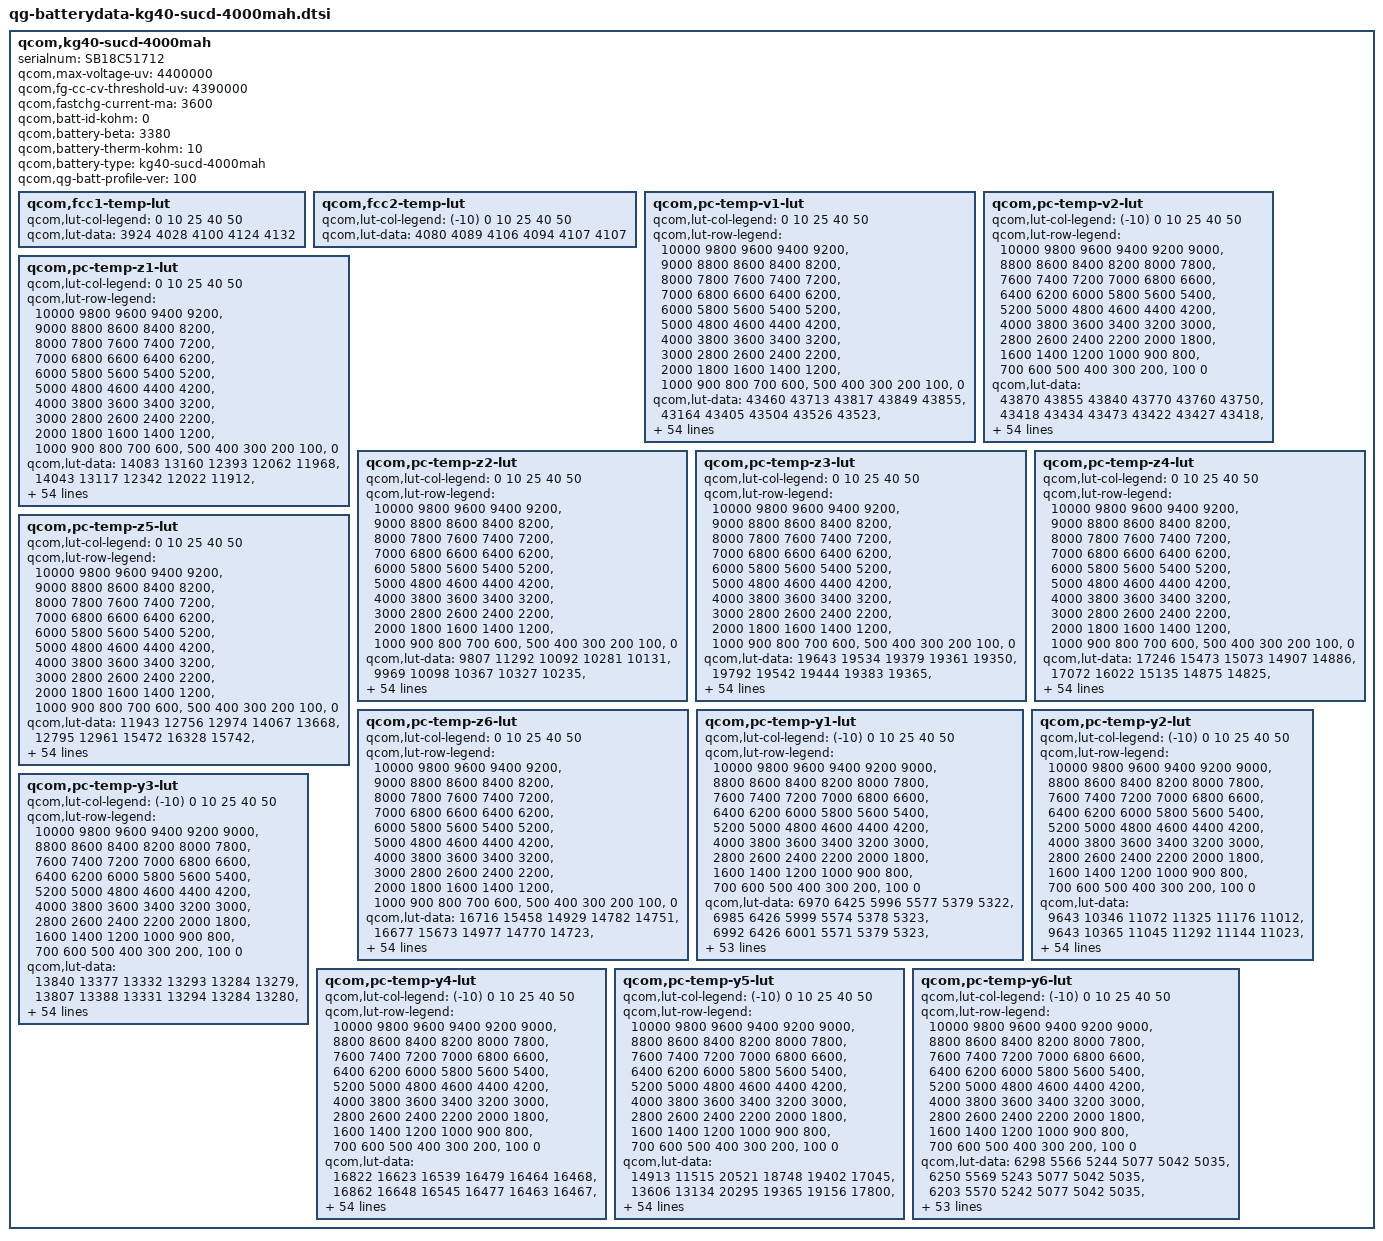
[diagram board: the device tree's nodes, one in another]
qcom,kg40-sucd-4000mah {
    /* 4123832_Huaqin_QL1883_SCUD_4000mAH_PMI632_averaged_MasterSlave_Aug21th2019 */
    serialnum = "SB18C51712";
    qcom,max-voltage-uv = <4400000>;
    qcom,fg-cc-cv-threshold-uv = <4390000>;
    qcom,fastchg-current-ma = <3600>;
    qcom,batt-id-kohm = <0>;
    qcom,battery-beta = <3380>;
    qcom,battery-therm-kohm = <10>;
    qcom,battery-type = "kg40-sucd-4000mah";
    qcom,qg-batt-profile-ver = <100>;

	qcom,fcc1-temp-lut {
		qcom,lut-col-legend = <0 10 25 40 50>;
		qcom,lut-data = <3924 4028 4100 4124 4132>;
	};

	qcom,fcc2-temp-lut {
		qcom,lut-col-legend = <(-10) 0 10 25 40 50>;
		qcom,lut-data = <4080 4089 4106 4094 4107 4107>;
	};

	qcom,pc-temp-v1-lut {
		qcom,lut-col-legend = <0 10 25 40 50>;
		qcom,lut-row-legend = <10000 9800 9600 9400 9200>,
			<9000 8800 8600 8400 8200>,
			<8000 7800 7600 7400 7200>,
			<7000 6800 6600 6400 6200>,
			<6000 5800 5600 5400 5200>,
			<5000 4800 4600 4400 4200>,
			<4000 3800 3600 3400 3200>,
			<3000 2800 2600 2400 2200>,
			<2000 1800 1600 1400 1200>,
			<1000 900 800 700 600>,
			<500 400 300 200 100>,
			<0>;
		qcom,lut-data = <43460 43713 43817 43849 43855>,
			<43164 43405 43504 43526 43523>,
			<42900 43133 43234 43255 43247>,
			<42664 42876 42982 43007 43000>,
			<42441 42632 42736 42766 42763>,
			<42220 42399 42493 42527 42527>,
			<42005 42171 42258 42294 42295>,
			<41794 41950 42031 42061 42065>,
			<41584 41734 41809 41831 41837>,
			<41382 41515 41589 41605 41611>,
			<41208 41306 41366 41382 41386>,
			<41050 41134 41157 41165 41167>,
			<40855 40986 40980 40957 40955>,
			<40555 40796 40809 40758 40752>,
			<40247 40483 40584 40558 40554>,
			<40042 40174 40296 40354 40360>,
			<39884 39999 40069 40161 40174>,
			<39750 39875 39933 39991 40000>,
			<39635 39756 39818 39833 39834>,
			<39530 39639 39687 39684 39680>,
			<39420 39520 39549 39548 39543>,
			<39308 39391 39379 39387 39384>,
			<39195 39252 39129 39128 39135>,
			<39082 39084 38889 38862 38870>,
			<38970 38844 38736 38717 38720>,
			<38861 38626 38619 38623 38621>,
			<38756 38505 38525 38533 38528>,
			<38656 38417 38452 38440 38429>,
			<38560 38357 38385 38353 38336>,
			<38469 38317 38316 38275 38255>,
			<38394 38283 38252 38203 38183>,
			<38328 38249 38193 38139 38119>,
			<38275 38215 38140 38084 38064>,
			<38236 38182 38092 38033 38011>,
			<38207 38150 38054 37988 37960>,
			<38176 38117 38018 37945 37910>,
			<38146 38088 37981 37900 37857>,
			<38112 38057 37945 37854 37803>,
			<38068 38012 37897 37796 37738>,
			<38013 37939 37820 37717 37652>,
			<37939 37846 37723 37621 37551>,
			<37825 37734 37617 37515 37443>,
			<37687 37599 37492 37392 37320>,
			<37525 37442 37336 37236 37159>,
			<37375 37288 37182 37087 37013>,
			<37256 37173 37075 36990 36930>,
			<37215 37135 37048 36964 36905>,
			<37181 37120 37028 36944 36885>,
			<37153 37097 37010 36926 36868>,
			<37121 37070 36983 36895 36829>,
			<37010 36947 36829 36709 36618>,
			<36622 36544 36427 36294 36199>,
			<36066 35987 35862 35729 35633>,
			<35308 35223 35095 34959 34858>,
			<34121 34039 33907 33766 33659>,
			<30000 30000 30000 30000 30000>;
	};

	qcom,pc-temp-v2-lut {
		qcom,lut-col-legend = <(-10) 0 10 25 40 50>;
		qcom,lut-row-legend = <10000 9800 9600 9400 9200 9000>,
			<8800 8600 8400 8200 8000 7800>,
			<7600 7400 7200 7000 6800 6600>,
			<6400 6200 6000 5800 5600 5400>,
			<5200 5000 4800 4600 4400 4200>,
			<4000 3800 3600 3400 3200 3000>,
			<2800 2600 2400 2200 2000 1800>,
			<1600 1400 1200 1000 900 800>,
			<700 600 500 400 300 200>,
			<100 0>;
		qcom,lut-data = <43870 43855 43840 43770 43760 43750>,
			<43418 43434 43473 43422 43427 43418>,
			<43023 43066 43143 43108 43123 43115>,
			<42693 42765 42856 42833 42852 42846>,
			<42414 42516 42606 42593 42611 42606>,
			<42171 42276 42364 42358 42376 42372>,
			<41969 42038 42126 42124 42142 42138>,
			<41779 41802 41894 41893 41911 41907>,
			<41542 41551 41666 41667 41683 41679>,
			<41269 41287 41442 41444 41459 41454>,
			<41090 41087 41235 41227 41238 41233>,
			<41015 40967 41054 41021 41022 41017>,
			<40936 40842 40868 40815 40810 40805>,
			<40640 40602 40635 40598 40606 40601>,
			<40064 40258 40374 40377 40406 40402>,
			<39687 39976 40143 40177 40216 40211>,
			<39491 39754 39939 39995 40035 40028>,
			<39330 39559 39754 39828 39863 39854>,
			<39166 39384 39595 39684 39702 39692>,
			<39013 39224 39445 39549 39548 39536>,
			<38862 39055 39262 39382 39385 39377>,
			<38711 38875 39041 39172 39216 39218>,
			<38573 38708 38841 38963 39034 39043>,
			<38445 38560 38677 38764 38810 38816>,
			<38330 38426 38533 38580 38593 38594>,
			<38239 38303 38409 38442 38451 38450>,
			<38164 38187 38301 38334 38345 38343>,
			<38098 38099 38202 38239 38250 38247>,
			<38038 38037 38108 38155 38162 38158>,
			<37982 37987 38025 38080 38083 38077>,
			<37930 37943 37957 38010 38014 38006>,
			<37881 37904 37899 37943 37951 37941>,
			<37832 37865 37854 37884 37891 37881>,
			<37782 37827 37821 37831 37834 37827>,
			<37731 37789 37791 37782 37775 37769>,
			<37676 37748 37758 37734 37708 37694>,
			<37616 37705 37725 37687 37636 37607>,
			<37554 37655 37683 37632 37559 37517>,
			<37489 37597 37631 37568 37477 37419>,
			<37422 37529 37566 37496 37394 37326>,
			<37357 37446 37484 37416 37318 37249>,
			<37291 37346 37383 37322 37232 37167>,
			<37223 37227 37260 37202 37124 37063>,
			<37153 37109 37122 37072 36985 36924>,
			<37071 37006 36988 36938 36858 36798>,
			<36967 36924 36906 36873 36805 36749>,
			<36910 36890 36881 36859 36795 36739>,
			<36841 36854 36845 36841 36783 36727>,
			<36736 36815 36808 36823 36761 36706>,
			<36573 36722 36735 36762 36701 36636>,
			<36271 36508 36513 36554 36455 36367>,
			<35839 36080 36062 36083 35971 35871>,
			<35237 35457 35431 35460 35328 35224>,
			<34380 34561 34551 34630 34471 34353>,
			<33024 33296 33337 33371 33257 33129>,
			<29294 28717 28615 28260 28466 28435>;
	};

	qcom,pc-temp-z1-lut {
		qcom,lut-col-legend = <0 10 25 40 50>;
		qcom,lut-row-legend = <10000 9800 9600 9400 9200>,
			<9000 8800 8600 8400 8200>,
			<8000 7800 7600 7400 7200>,
			<7000 6800 6600 6400 6200>,
			<6000 5800 5600 5400 5200>,
			<5000 4800 4600 4400 4200>,
			<4000 3800 3600 3400 3200>,
			<3000 2800 2600 2400 2200>,
			<2000 1800 1600 1400 1200>,
			<1000 900 800 700 600>,
			<500 400 300 200 100>,
			<0>;
		qcom,lut-data = <14083 13160 12393 12062 11968>,
			<14043 13117 12342 12022 11912>,
			<14018 13088 12329 11999 11903>,
			<14003 13072 12314 11991 11898>,
			<13988 13063 12303 11987 11895>,
			<13966 13059 12293 11984 11895>,
			<13942 13053 12285 11982 11895>,
			<13930 13035 12280 11983 11897>,
			<13919 13025 12275 11985 11901>,
			<13909 13025 12275 11986 11903>,
			<13906 13023 12281 11986 11903>,
			<13902 13013 12284 11987 11903>,
			<13893 12991 12283 11987 11903>,
			<13858 12970 12280 11987 11904>,
			<13812 12952 12275 11987 11904>,
			<13776 12939 12262 11987 11905>,
			<13734 12941 12256 11987 11906>,
			<13716 12949 12262 11988 11908>,
			<13725 12957 12273 11989 11910>,
			<13736 12964 12281 11992 11912>,
			<13737 12973 12290 11995 11913>,
			<13735 12984 12296 11998 11915>,
			<13739 12997 12301 12000 11917>,
			<13755 13006 12304 12002 11918>,
			<13777 13015 12308 12005 11921>,
			<13794 13021 12312 12009 11925>,
			<13809 13028 12317 12013 11928>,
			<13819 13035 12324 12018 11932>,
			<13820 13037 12330 12023 11935>,
			<13816 13033 12336 12027 11938>,
			<13816 13029 12342 12031 11941>,
			<13816 13044 12347 12033 11944>,
			<13820 13078 12351 12036 11947>,
			<13829 13092 12355 12038 11950>,
			<13841 13091 12363 12042 11952>,
			<13861 13091 12373 12047 11955>,
			<13909 13096 12380 12052 11958>,
			<13949 13107 12386 12056 11961>,
			<13949 13118 12393 12060 11964>,
			<13942 13131 12400 12065 11968>,
			<13936 13141 12407 12070 11971>,
			<13935 13150 12418 12074 11974>,
			<13942 13160 12430 12078 11977>,
			<13993 13185 12432 12082 11979>,
			<13972 13187 12439 12088 11982>,
			<13968 13201 12453 12090 11983>,
			<13964 13205 12448 12090 11983>,
			<13930 13179 12448 12092 11984>,
			<13961 13185 12455 12092 11986>,
			<13969 13186 12460 12098 11991>,
			<13992 13211 12467 12104 11996>,
			<14020 13240 12476 12112 12004>,
			<14010 13240 12506 12126 12014>,
			<14064 13295 12523 12143 12028>,
			<14064 13295 12523 12143 12028>,
			<14064 13295 12523 12143 12028>;
	};

	qcom,pc-temp-z2-lut {
		qcom,lut-col-legend = <0 10 25 40 50>;
		qcom,lut-row-legend = <10000 9800 9600 9400 9200>,
			<9000 8800 8600 8400 8200>,
			<8000 7800 7600 7400 7200>,
			<7000 6800 6600 6400 6200>,
			<6000 5800 5600 5400 5200>,
			<5000 4800 4600 4400 4200>,
			<4000 3800 3600 3400 3200>,
			<3000 2800 2600 2400 2200>,
			<2000 1800 1600 1400 1200>,
			<1000 900 800 700 600>,
			<500 400 300 200 100>,
			<0>;
		qcom,lut-data = <9807 11292 10092 10281 10131>,
			<9969 10098 10367 10327 10235>,
			<10049 10134 10383 10411 10350>,
			<10092 10151 10372 10397 10364>,
			<10112 10128 10359 10379 10369>,
			<10104 10092 10322 10352 10348>,
			<10081 10065 10294 10324 10309>,
			<10064 10040 10478 10315 10289>,
			<10055 10026 10863 10309 10276>,
			<10046 10019 11017 10310 10272>,
			<10034 10014 11073 10317 10286>,
			<10019 10072 11095 10325 10303>,
			<10002 10250 11067 10328 10290>,
			<9977 10322 10996 10331 10246>,
			<9951 10215 10845 10332 10224>,
			<9931 10101 10510 10331 10215>,
			<9914 10099 10342 10328 10213>,
			<9907 10120 10337 10314 10224>,
			<9909 10145 10335 10291 10245>,
			<9914 10176 10348 10289 10268>,
			<9918 10209 10393 10308 10294>,
			<9924 10241 10433 10340 10336>,
			<9930 10273 10469 10512 10515>,
			<9937 10281 10492 10714 10732>,
			<9944 10266 10454 10666 10705>,
			<9955 10252 10364 10430 10493>,
			<9977 10259 10342 10334 10395>,
			<10000 10279 10374 10415 10414>,
			<10021 10290 10402 10495 10434>,
			<10040 10295 10405 10464 10397>,
			<10057 10299 10407 10381 10291>,
			<10073 10304 10407 10344 10223>,
			<10088 10310 10405 10330 10181>,
			<10100 10318 10404 10324 10161>,
			<10112 10330 10409 10340 10182>,
			<10128 10344 10420 10375 10230>,
			<10153 10357 10435 10411 10278>,
			<10178 10372 10459 10453 10334>,
			<10181 10389 10483 10480 10378>,
			<10163 10413 10506 10494 10409>,
			<10165 10436 10526 10502 10431>,
			<10203 10451 10540 10508 10438>,
			<10242 10466 10551 10520 10443>,
			<10281 10483 10552 10517 10481>,
			<10000 10590 10566 10498 10498>,
			<10023 10720 10605 10477 10405>,
			<11487 10724 10606 10483 10418>,
			<9940 11479 10621 10486 10428>,
			<9979 11787 10598 10493 10467>,
			<10034 11837 10633 10588 10558>,
			<9947 11635 10664 10492 10422>,
			<9870 10790 10621 10367 10247>,
			<9801 10785 10555 10287 10170>,
			<9677 10702 10481 10238 10096>,
			<9677 10702 10481 10238 10096>,
			<9677 10702 10481 10238 10096>;
	};

	qcom,pc-temp-z3-lut {
		qcom,lut-col-legend = <0 10 25 40 50>;
		qcom,lut-row-legend = <10000 9800 9600 9400 9200>,
			<9000 8800 8600 8400 8200>,
			<8000 7800 7600 7400 7200>,
			<7000 6800 6600 6400 6200>,
			<6000 5800 5600 5400 5200>,
			<5000 4800 4600 4400 4200>,
			<4000 3800 3600 3400 3200>,
			<3000 2800 2600 2400 2200>,
			<2000 1800 1600 1400 1200>,
			<1000 900 800 700 600>,
			<500 400 300 200 100>,
			<0>;
		qcom,lut-data = <19643 19534 19379 19361 19350>,
			<19792 19542 19444 19383 19365>,
			<19821 19627 19473 19415 19404>,
			<19772 19669 19482 19420 19410>,
			<19720 19668 19483 19422 19412>,
			<19697 19668 19483 19424 19414>,
			<19680 19664 19483 19426 19415>,
			<19677 19655 19491 19425 19414>,
			<19686 19648 19508 19420 19410>,
			<19697 19644 19511 19416 19406>,
			<19703 19640 19506 19410 19404>,
			<19708 19638 19499 19404 19402>,
			<19717 19636 19492 19399 19397>,
			<19771 19632 19483 19393 19388>,
			<19828 19622 19474 19391 19382>,
			<19825 19607 19463 19390 19378>,
			<19789 19586 19453 19390 19376>,
			<19758 19558 19442 19386 19372>,
			<19739 19542 19431 19379 19368>,
			<19723 19536 19422 19372 19363>,
			<19709 19533 19415 19364 19354>,
			<19696 19532 19414 19361 19349>,
			<19690 19532 19429 19375 19361>,
			<19696 19533 19444 19394 19377>,
			<19707 19543 19438 19388 19374>,
			<19712 19552 19423 19362 19355>,
			<19716 19552 19418 19352 19347>,
			<19718 19553 19420 19376 19378>,
			<19718 19553 19422 19401 19411>,
			<19715 19550 19429 19405 19410>,
			<19712 19547 19438 19407 19402>,
			<19705 19543 19440 19406 19393>,
			<19696 19539 19439 19400 19383>,
			<19684 19536 19439 19392 19373>,
			<19670 19533 19435 19386 19365>,
			<19655 19530 19430 19380 19359>,
			<19640 19525 19425 19375 19355>,
			<19621 19518 19421 19371 19351>,
			<19579 19513 19418 19368 19350>,
			<19506 19509 19417 19366 19350>,
			<19475 19505 19415 19365 19350>,
			<19474 19500 19411 19363 19351>,
			<19473 19495 19406 19362 19351>,
			<19462 19488 19404 19362 19355>,
			<19332 19463 19399 19361 19358>,
			<19266 19438 19390 19354 19347>,
			<19262 19438 19384 19348 19340>,
			<19266 19309 19378 19344 19335>,
			<19265 19287 19374 19342 19324>,
			<19264 19281 19369 19331 19320>,
			<19265 19297 19374 19347 19336>,
			<19266 19426 19375 19362 19351>,
			<19267 19383 19383 19364 19354>,
			<19270 19387 19374 19363 19359>,
			<19270 19387 19374 19363 19359>,
			<19270 19387 19374 19363 19359>;
	};

	qcom,pc-temp-z4-lut {
		qcom,lut-col-legend = <0 10 25 40 50>;
		qcom,lut-row-legend = <10000 9800 9600 9400 9200>,
			<9000 8800 8600 8400 8200>,
			<8000 7800 7600 7400 7200>,
			<7000 6800 6600 6400 6200>,
			<6000 5800 5600 5400 5200>,
			<5000 4800 4600 4400 4200>,
			<4000 3800 3600 3400 3200>,
			<3000 2800 2600 2400 2200>,
			<2000 1800 1600 1400 1200>,
			<1000 900 800 700 600>,
			<500 400 300 200 100>,
			<0>;
		qcom,lut-data = <17246 15473 15073 14907 14886>,
			<17072 16022 15135 14875 14825>,
			<16839 15713 15165 14953 14889>,
			<16513 15444 15027 14902 14858>,
			<16203 15279 14933 14850 14822>,
			<15989 15149 14884 14818 14797>,
			<15813 15055 14840 14792 14775>,
			<15668 14982 14782 14768 14756>,
			<15549 14926 14724 14747 14739>,
			<15444 14888 14697 14735 14728>,
			<15339 14852 14686 14730 14720>,
			<15239 14797 14676 14725 14714>,
			<15163 14725 14660 14719 14711>,
			<15110 14700 14646 14711 14709>,
			<15066 14743 14655 14705 14706>,
			<15025 14790 14705 14702 14702>,
			<14987 14786 14732 14699 14697>,
			<14951 14762 14709 14694 14693>,
			<14914 14740 14682 14689 14689>,
			<14880 14717 14680 14686 14684>,
			<14857 14702 14682 14684 14680>,
			<14841 14701 14688 14683 14678>,
			<14825 14701 14748 14741 14733>,
			<14804 14709 14814 14819 14811>,
			<14786 14789 14835 14835 14822>,
			<14776 14864 14848 14840 14823>,
			<14770 14866 14848 14840 14821>,
			<14768 14865 14822 14798 14773>,
			<14771 14860 14791 14747 14718>,
			<14776 14835 14764 14726 14707>,
			<14778 14805 14739 14712 14703>,
			<14777 14783 14724 14703 14699>,
			<14775 14764 14714 14698 14695>,
			<14769 14748 14708 14695 14693>,
			<14757 14734 14704 14692 14691>,
			<14748 14723 14702 14691 14689>,
			<14741 14712 14698 14691 14689>,
			<14736 14703 14694 14692 14691>,
			<14755 14698 14692 14693 14694>,
			<14815 14696 14695 14699 14701>,
			<14838 14693 14697 14705 14709>,
			<14827 14689 14693 14701 14705>,
			<14818 14684 14682 14691 14693>,
			<14814 14681 14679 14691 14695>,
			<14890 14674 14672 14686 14692>,
			<14931 14663 14651 14664 14665>,
			<14924 14654 14645 14658 14661>,
			<14915 14790 14638 14646 14650>,
			<14909 14809 14632 14629 14637>,
			<14904 14811 14633 14630 14627>,
			<14904 14796 14641 14640 14648>,
			<14928 14671 14657 14647 14656>,
			<14946 14732 14657 14651 14659>,
			<14963 14740 14673 14657 14658>,
			<14963 14740 14673 14657 14658>,
			<14963 14740 14673 14657 14658>;
	};

	qcom,pc-temp-z5-lut {
		qcom,lut-col-legend = <0 10 25 40 50>;
		qcom,lut-row-legend = <10000 9800 9600 9400 9200>,
			<9000 8800 8600 8400 8200>,
			<8000 7800 7600 7400 7200>,
			<7000 6800 6600 6400 6200>,
			<6000 5800 5600 5400 5200>,
			<5000 4800 4600 4400 4200>,
			<4000 3800 3600 3400 3200>,
			<3000 2800 2600 2400 2200>,
			<2000 1800 1600 1400 1200>,
			<1000 900 800 700 600>,
			<500 400 300 200 100>,
			<0>;
		qcom,lut-data = <11943 12756 12974 14067 13668>,
			<12795 12961 15472 16328 15742>,
			<13142 14063 15811 16997 18124>,
			<13246 15042 16735 17531 18912>,
			<13332 15634 17565 18103 19467>,
			<13460 16162 18150 18694 20106>,
			<13609 16734 18927 19313 20701>,
			<13793 17324 20935 19977 21294>,
			<14046 18056 24131 20737 21873>,
			<14323 19029 26621 21196 22503>,
			<14550 20285 28496 21292 23441>,
			<14759 22299 30428 21259 24200>,
			<15182 25218 33292 21236 23897>,
			<17245 26688 35882 21279 22814>,
			<19370 26936 34934 21603 22452>,
			<19327 26784 29235 22667 23055>,
			<18379 25475 26224 23679 23831>,
			<17830 22692 26585 24206 24501>,
			<17875 21740 27112 24582 25160>,
			<18051 23750 27401 24474 25140>,
			<18260 26911 27833 23576 24095>,
			<18566 29868 29168 23075 23412>,
			<19069 33306 39935 28565 26870>,
			<20814 37895 49952 35703 31842>,
			<23851 46273 44114 33012 29990>,
			<27101 52518 29364 21348 20342>,
			<31201 50722 23544 16527 15977>,
			<35117 45256 22088 18176 20005>,
			<38853 41174 21499 20750 24839>,
			<42287 38206 22874 23421 26375>,
			<43136 36259 26070 26409 27272>,
			<42942 35531 29269 28447 27408>,
			<42536 35084 32973 29871 26780>,
			<40873 35132 35691 30930 26282>,
			<37115 36514 37323 31859 26631>,
			<33710 37946 38352 32585 27309>,
			<30789 38128 38395 32621 27597>,
			<27968 37797 38125 32185 27597>,
			<24596 38143 37820 31538 27451>,
			<20481 39563 37376 30171 26763>,
			<18987 40549 36655 28454 25856>,
			<20463 39813 34728 27068 25347>,
			<21441 38080 32055 26010 24980>,
			<21271 35575 31752 26318 27433>,
			<14954 31821 32182 26799 29507>,
			<11535 27993 32869 26215 26237>,
			<11483 28963 29328 23395 21966>,
			<11505 12720 27120 23867 22201>,
			<11483 11954 26269 27206 21733>,
			<11495 11841 24842 22664 23209>,
			<11528 12304 24836 26455 25233>,
			<11597 23305 21237 24789 22799>,
			<11490 16920 21761 22759 20749>,
			<11419 16004 18097 19746 19447>,
			<11419 16004 18097 19746 19447>,
			<11419 16004 18097 19746 19447>;
	};

	qcom,pc-temp-z6-lut {
		qcom,lut-col-legend = <0 10 25 40 50>;
		qcom,lut-row-legend = <10000 9800 9600 9400 9200>,
			<9000 8800 8600 8400 8200>,
			<8000 7800 7600 7400 7200>,
			<7000 6800 6600 6400 6200>,
			<6000 5800 5600 5400 5200>,
			<5000 4800 4600 4400 4200>,
			<4000 3800 3600 3400 3200>,
			<3000 2800 2600 2400 2200>,
			<2000 1800 1600 1400 1200>,
			<1000 900 800 700 600>,
			<500 400 300 200 100>,
			<0>;
		qcom,lut-data = <16716 15458 14929 14782 14751>,
			<16677 15673 14977 14770 14723>,
			<16590 15564 15000 14817 14767>,
			<16403 15459 14944 14797 14756>,
			<16209 15381 14903 14776 14743>,
			<16085 15312 14878 14763 14734>,
			<15983 15259 14858 14752 14726>,
			<15906 15216 14839 14741 14717>,
			<15849 15182 14823 14731 14708>,
			<15799 15159 14813 14723 14702>,
			<15745 15138 14806 14717 14697>,
			<15691 15107 14799 14712 14694>,
			<15657 15069 14786 14706 14689>,
			<15641 15056 14773 14699 14683>,
			<15627 15058 14773 14696 14678>,
			<15599 15061 14784 14694 14675>,
			<15554 15053 14789 14692 14671>,
			<15515 15028 14775 14688 14667>,
			<15486 15011 14758 14682 14664>,
			<15463 15001 14755 14677 14659>,
			<15448 14996 14754 14673 14653>,
			<15437 14996 14755 14671 14649>,
			<15432 14999 14792 14705 14679>,
			<15433 15006 14828 14749 14722>,
			<15436 15046 14832 14752 14726>,
			<15439 15084 14833 14743 14719>,
			<15442 15088 14832 14736 14712>,
			<15446 15090 14823 14731 14708>,
			<15452 15089 14813 14725 14704>,
			<15459 15080 14807 14720 14700>,
			<15460 15067 14802 14716 14694>,
			<15457 15059 14797 14711 14688>,
			<15453 15051 14794 14705 14682>,
			<15448 15045 14791 14701 14676>,
			<15441 15039 14788 14696 14670>,
			<15434 15035 14785 14693 14666>,
			<15428 15032 14783 14690 14664>,
			<15423 15029 14780 14689 14663>,
			<15419 15029 14779 14688 14663>,
			<15415 15030 14781 14690 14666>,
			<15414 15031 14783 14692 14670>,
			<15415 15032 14781 14690 14669>,
			<15417 15032 14775 14686 14664>,
			<15419 15031 14775 14686 14668>,
			<15400 15025 14772 14684 14668>,
			<15387 15010 14760 14672 14651>,
			<15385 15008 14755 14667 14646>,
			<15382 15000 14749 14659 14638>,
			<15380 14999 14745 14651 14627>,
			<15380 15000 14744 14646 14621>,
			<15391 15008 14753 14660 14639>,
			<15410 15027 14764 14673 14653>,
			<15431 15042 14773 14679 14659>,
			<15461 15064 14782 14685 14665>,
			<15461 15064 14782 14685 14665>,
			<15461 15064 14782 14685 14665>;
	};

	qcom,pc-temp-y1-lut {
		qcom,lut-col-legend = <(-10) 0 10 25 40 50>;
		qcom,lut-row-legend = <10000 9800 9600 9400 9200 9000>,
			<8800 8600 8400 8200 8000 7800>,
			<7600 7400 7200 7000 6800 6600>,
			<6400 6200 6000 5800 5600 5400>,
			<5200 5000 4800 4600 4400 4200>,
			<4000 3800 3600 3400 3200 3000>,
			<2800 2600 2400 2200 2000 1800>,
			<1600 1400 1200 1000 900 800>,
			<700 600 500 400 300 200>,
			<100 0>;
		qcom,lut-data = <6970 6425 5996 5577 5379 5322>,
			<6985 6426 5999 5574 5378 5323>,
			<6992 6426 6001 5571 5379 5323>,
			<6992 6424 6002 5568 5379 5324>,
			<6987 6421 6002 5565 5380 5324>,
			<6978 6418 6001 5563 5380 5325>,
			<6949 6411 5998 5563 5380 5325>,
			<6917 6406 5994 5562 5381 5326>,
			<6917 6407 5991 5562 5381 5326>,
			<6927 6413 5987 5561 5381 5326>,
			<6932 6416 5985 5561 5381 5326>,
			<6928 6412 5983 5560 5382 5326>,
			<6925 6408 5982 5559 5382 5327>,
			<6939 6412 5981 5559 5382 5328>,
			<6978 6422 5978 5561 5382 5329>,
			<6996 6431 5981 5564 5382 5330>,
			<6995 6443 5994 5571 5385 5330>,
			<6993 6451 6005 5576 5387 5331>,
			<6996 6447 6003 5575 5388 5332>,
			<6999 6439 5998 5573 5388 5333>,
			<6995 6439 5999 5573 5389 5334>,
			<6971 6454 6004 5577 5390 5335>,
			<6953 6464 6010 5581 5391 5336>,
			<6958 6463 6012 5584 5392 5337>,
			<6968 6460 6012 5588 5394 5339>,
			<6964 6457 6011 5590 5396 5340>,
			<6943 6450 6007 5593 5399 5341>,
			<6932 6443 6008 5596 5401 5343>,
			<6947 6440 6016 5599 5403 5344>,
			<6970 6440 6024 5604 5405 5346>,
			<6964 6439 6021 5609 5408 5348>,
			<6931 6437 6012 5616 5411 5351>,
			<6915 6439 6011 5620 5414 5354>,
			<6946 6448 6015 5622 5417 5356>,
			<6981 6456 6020 5623 5421 5359>,
			<6978 6456 6027 5627 5422 5360>,
			<6960 6453 6034 5633 5424 5361>,
			<6954 6458 6035 5636 5426 5362>,
			<6977 6537 6032 5637 5428 5364>,
			<6999 6606 6032 5639 5430 5365>,
			<6990 6540 6039 5644 5431 5367>,
			<6967 6446 6048 5651 5433 5368>,
			<6947 6453 6056 5651 5435 5370>,
			<6950 6458 6059 5656 5439 5373>,
			<7020 6511 6067 5673 5445 5377>,
			<7020 6519 6091 5677 5450 5381>,
			<7044 6504 6073 5682 5451 5380>,
			<7040 6514 6079 5688 5450 5379>,
			<7063 6530 6085 5688 5449 5379>,
			<7039 6500 6080 5691 5450 5379>,
			<7072 6497 6085 5686 5452 5382>,
			<7083 6545 6093 5694 5458 5387>,
			<7095 6551 6112 5721 5468 5395>,
			<7231 6576 6137 5744 5480 5405>,
			<7231 6576 6137 5744 5480 5405>,
			<7231 6576 6137 5744 5480 5405>;
	};

	qcom,pc-temp-y2-lut {
		qcom,lut-col-legend = <(-10) 0 10 25 40 50>;
		qcom,lut-row-legend = <10000 9800 9600 9400 9200 9000>,
			<8800 8600 8400 8200 8000 7800>,
			<7600 7400 7200 7000 6800 6600>,
			<6400 6200 6000 5800 5600 5400>,
			<5200 5000 4800 4600 4400 4200>,
			<4000 3800 3600 3400 3200 3000>,
			<2800 2600 2400 2200 2000 1800>,
			<1600 1400 1200 1000 900 800>,
			<700 600 500 400 300 200>,
			<100 0>;
		qcom,lut-data = <9643 10346 11072 11325 11176 11012>,
			<9643 10365 11045 11292 11144 11023>,
			<9658 10390 11015 11256 11105 11022>,
			<9769 10413 10982 11219 11066 11012>,
			<9871 10433 10947 11182 11032 10995>,
			<9960 10442 10911 11145 11008 10972>,
			<10029 10445 10867 11105 10986 10930>,
			<10100 10446 10828 11067 10971 10889>,
			<10245 10440 10805 11040 10965 10880>,
			<10478 10422 10788 11019 10946 10881>,
			<10567 10425 10771 10992 10929 10878>,
			<10513 10574 10747 10943 10904 10848>,
			<10456 10721 10731 10905 10877 10820>,
			<10491 10720 10786 10910 10852 10812>,
			<10593 10700 10912 10928 10827 10798>,
			<10592 10698 10970 10952 10828 10791>,
			<10147 10751 10988 10986 10880 10784>,
			<9744 10817 11005 11030 10946 10780>,
			<9718 10863 11037 11100 10996 10821>,
			<9709 10904 11070 11180 11051 10915>,
			<9702 10943 11076 11211 11141 11043>,
			<9695 10984 11071 11224 11293 11245>,
			<9690 11004 11070 11231 11365 11339>,
			<9685 10991 11100 11232 11278 11239>,
			<9681 10964 11146 11233 11164 11114>,
			<9679 10873 11170 11236 11144 11109>,
			<9678 10554 11186 11247 11149 11136>,
			<9677 10382 11200 11259 11161 11165>,
			<9676 10381 11212 11272 11186 11229>,
			<9675 10381 11221 11287 11220 11285>,
			<9674 10381 11227 11297 11264 11280>,
			<9672 10376 11233 11307 11313 11259>,
			<9670 10339 11232 11311 11324 11257>,
			<9668 10053 11215 11312 11306 11289>,
			<9667 9767 11190 11312 11283 11315>,
			<9666 9719 11167 11305 11266 11294>,
			<9665 9698 11141 11289 11248 11245>,
			<9664 9687 11113 11275 11221 11199>,
			<9663 9681 11083 11254 11172 11147>,
			<9662 9676 11045 11236 11146 11107>,
			<9662 9671 10990 11218 11175 11076>,
			<9661 9667 10922 11191 11199 11063>,
			<9660 9664 10832 11162 11188 11090>,
			<9660 9662 10737 11126 11142 11072>,
			<9659 9661 10710 11155 11112 11025>,
			<9658 9659 10442 11058 10963 10842>,
			<9658 9658 10343 11013 10954 10807>,
			<9657 9657 9983 10982 10961 10811>,
			<9657 9656 9842 10992 10973 10866>,
			<9657 9656 9747 10988 10978 10869>,
			<9656 9656 9709 10978 10966 10807>,
			<9656 9655 9682 10921 10913 10735>,
			<9655 9655 9667 10814 10816 10651>,
			<9652 9654 9660 10757 10708 10515>,
			<9652 9654 9660 10757 10708 10515>,
			<9652 9654 9660 10757 10708 10515>;
	};

	qcom,pc-temp-y3-lut {
		qcom,lut-col-legend = <(-10) 0 10 25 40 50>;
		qcom,lut-row-legend = <10000 9800 9600 9400 9200 9000>,
			<8800 8600 8400 8200 8000 7800>,
			<7600 7400 7200 7000 6800 6600>,
			<6400 6200 6000 5800 5600 5400>,
			<5200 5000 4800 4600 4400 4200>,
			<4000 3800 3600 3400 3200 3000>,
			<2800 2600 2400 2200 2000 1800>,
			<1600 1400 1200 1000 900 800>,
			<700 600 500 400 300 200>,
			<100 0>;
		qcom,lut-data = <13840 13377 13332 13293 13284 13279>,
			<13807 13388 13331 13294 13284 13280>,
			<13745 13400 13332 13295 13284 13281>,
			<13675 13412 13332 13296 13284 13282>,
			<13619 13420 13334 13297 13284 13283>,
			<13596 13422 13336 13298 13284 13283>,
			<13594 13420 13339 13299 13285 13284>,
			<13592 13417 13342 13300 13286 13284>,
			<13581 13418 13344 13300 13286 13285>,
			<13548 13424 13346 13301 13287 13285>,
			<13513 13424 13348 13302 13288 13285>,
			<13471 13397 13355 13303 13289 13286>,
			<13440 13370 13360 13304 13289 13287>,
			<13439 13374 13357 13306 13290 13287>,
			<13441 13388 13349 13309 13291 13288>,
			<13441 13392 13346 13309 13292 13289>,
			<13432 13388 13346 13308 13294 13289>,
			<13423 13384 13345 13308 13296 13289>,
			<13420 13379 13343 13307 13296 13291>,
			<13419 13375 13340 13306 13296 13293>,
			<13418 13369 13335 13305 13296 13293>,
			<13417 13362 13330 13304 13295 13293>,
			<13415 13355 13326 13302 13293 13292>,
			<13399 13351 13323 13298 13288 13286>,
			<13376 13348 13320 13295 13283 13280>,
			<13372 13338 13319 13293 13282 13279>,
			<13375 13313 13318 13292 13282 13279>,
			<13381 13300 13317 13292 13281 13279>,
			<13389 13299 13314 13293 13281 13279>,
			<13400 13300 13312 13294 13280 13278>,
			<13415 13305 13312 13294 13280 13278>,
			<13436 13325 13312 13293 13281 13278>,
			<13459 13338 13312 13293 13281 13278>,
			<13483 13343 13313 13293 13282 13278>,
			<13510 13348 13316 13294 13283 13279>,
			<13537 13356 13318 13294 13283 13280>,
			<13567 13366 13320 13294 13283 13280>,
			<13600 13378 13321 13295 13283 13280>,
			<13639 13394 13323 13295 13283 13280>,
			<13683 13414 13325 13295 13282 13280>,
			<13726 13444 13327 13296 13284 13281>,
			<13774 13483 13328 13296 13286 13283>,
			<13832 13532 13330 13297 13286 13283>,
			<13900 13593 13333 13297 13284 13281>,
			<13892 13590 13330 13293 13282 13279>,
			<13995 13706 13332 13295 13286 13284>,
			<14065 13777 13339 13300 13290 13287>,
			<14137 13852 13342 13302 13294 13290>,
			<14214 13914 13365 13309 13296 13292>,
			<14307 13992 13394 13311 13296 13291>,
			<14398 14053 13416 13311 13293 13287>,
			<14525 14136 13446 13310 13293 13287>,
			<14764 14249 13519 13317 13297 13293>,
			<15473 14394 13672 13329 13305 13301>,
			<15473 14394 13672 13329 13305 13301>,
			<15473 14394 13672 13329 13305 13301>;
	};

	qcom,pc-temp-y4-lut {
		qcom,lut-col-legend = <(-10) 0 10 25 40 50>;
		qcom,lut-row-legend = <10000 9800 9600 9400 9200 9000>,
			<8800 8600 8400 8200 8000 7800>,
			<7600 7400 7200 7000 6800 6600>,
			<6400 6200 6000 5800 5600 5400>,
			<5200 5000 4800 4600 4400 4200>,
			<4000 3800 3600 3400 3200 3000>,
			<2800 2600 2400 2200 2000 1800>,
			<1600 1400 1200 1000 900 800>,
			<700 600 500 400 300 200>,
			<100 0>;
		qcom,lut-data = <16822 16623 16539 16479 16464 16468>,
			<16862 16648 16545 16477 16463 16467>,
			<16893 16672 16554 16476 16463 16465>,
			<16915 16694 16563 16475 16464 16462>,
			<16929 16714 16571 16475 16464 16461>,
			<16933 16730 16575 16475 16464 16460>,
			<16921 16745 16575 16476 16464 16460>,
			<16907 16756 16576 16477 16464 16460>,
			<16911 16753 16579 16480 16465 16460>,
			<16934 16740 16589 16484 16467 16462>,
			<16979 16745 16601 16488 16469 16463>,
			<17199 16943 16614 16492 16471 16465>,
			<17412 17143 16631 16496 16474 16467>,
			<17264 17087 16663 16503 16478 16469>,
			<16845 16911 16705 16512 16485 16473>,
			<16705 16803 16712 16523 16491 16477>,
			<16750 16744 16691 16541 16495 16483>,
			<16790 16711 16676 16563 16501 16490>,
			<16785 16702 16678 16595 16517 16499>,
			<16771 16698 16682 16630 16541 16511>,
			<16752 16685 16671 16633 16559 16529>,
			<16722 16650 16611 16603 16575 16556>,
			<16703 16615 16561 16565 16581 16568>,
			<16705 16587 16537 16519 16532 16525>,
			<16707 16564 16519 16477 16470 16470>,
			<16708 16560 16510 16468 16462 16462>,
			<16706 16579 16505 16465 16461 16460>,
			<16705 16593 16500 16464 16460 16460>,
			<16705 16598 16494 16466 16464 16464>,
			<16704 16602 16489 16469 16471 16470>,
			<16702 16598 16486 16472 16479 16477>,
			<16697 16582 16484 16474 16489 16487>,
			<16694 16576 16484 16477 16494 16497>,
			<16695 16597 16489 16480 16497 16508>,
			<16695 16624 16497 16482 16499 16514>,
			<16696 16639 16507 16483 16494 16509>,
			<16699 16650 16519 16484 16485 16497>,
			<16703 16661 16531 16484 16477 16485>,
			<16710 16673 16543 16482 16469 16471>,
			<16721 16679 16554 16480 16466 16464>,
			<16734 16677 16563 16482 16472 16474>,
			<16751 16670 16568 16485 16478 16483>,
			<16776 16655 16569 16484 16479 16486>,
			<16793 16645 16563 16480 16468 16469>,
			<16752 16631 16531 16462 16446 16443>,
			<16765 16640 16553 16472 16453 16454>,
			<16784 16653 16568 16485 16470 16480>,
			<16810 16675 16607 16505 16498 16515>,
			<16820 16737 16647 16540 16536 16555>,
			<16825 16750 16698 16567 16557 16565>,
			<16820 16765 16708 16562 16510 16507>,
			<16824 16744 16703 16531 16478 16477>,
			<16879 16738 16719 16551 16484 16480>,
			<17221 16764 16764 16605 16532 16515>,
			<17221 16764 16764 16605 16532 16515>,
			<17221 16764 16764 16605 16532 16515>;
	};

	qcom,pc-temp-y5-lut {
		qcom,lut-col-legend = <(-10) 0 10 25 40 50>;
		qcom,lut-row-legend = <10000 9800 9600 9400 9200 9000>,
			<8800 8600 8400 8200 8000 7800>,
			<7600 7400 7200 7000 6800 6600>,
			<6400 6200 6000 5800 5600 5400>,
			<5200 5000 4800 4600 4400 4200>,
			<4000 3800 3600 3400 3200 3000>,
			<2800 2600 2400 2200 2000 1800>,
			<1600 1400 1200 1000 900 800>,
			<700 600 500 400 300 200>,
			<100 0>;
		qcom,lut-data = <14913 11515 20521 18748 19402 17045>,
			<13606 13134 20295 19365 19156 17800>,
			<13041 14786 20004 19816 18807 18433>,
			<13058 16233 19717 20098 18426 18915>,
			<13497 17238 19505 20205 18081 19214>,
			<14220 17563 19438 20132 17841 19299>,
			<16705 17314 19513 19847 17626 19127>,
			<19347 16819 19550 19431 17444 18870>,
			<18726 15986 19248 18906 17297 18568>,
			<15728 14585 18460 18137 17018 17975>,
			<14461 13898 17605 17405 16762 17513>,
			<15806 13736 16498 16587 16490 17178>,
			<17938 13710 15749 16005 16158 16858>,
			<20323 16175 15986 15946 15659 16549>,
			<23135 22010 16772 15976 15092 16243>,
			<23572 23741 17811 15869 15000 15848>,
			<18660 22435 19529 15253 15328 15270>,
			<14325 21351 21210 14784 15566 14868>,
			<14336 21932 22532 15019 15153 14741>,
			<14591 23067 23593 15722 14483 14667>,
			<14649 23301 23980 17196 15015 15073>,
			<14553 23081 24154 21098 18120 17106>,
			<14376 22932 24256 23637 19997 18557>,
			<13648 23250 24125 23885 20205 19026>,
			<12630 23730 23921 23837 20307 19298>,
			<12438 22514 23977 23361 20257 19343>,
			<12451 16767 24155 22208 20024 19301>,
			<12462 13532 24006 21693 19714 19153>,
			<12466 13346 22921 22858 18769 18208>,
			<12472 13258 21784 24284 17933 17201>,
			<12548 13579 21281 24513 18003 16865>,
			<12838 14618 20828 24426 18379 16632>,
			<13116 15019 20784 24381 18973 16703>,
			<13365 14380 21510 24516 20304 17993>,
			<13540 13750 22163 24646 21776 19790>,
			<13542 13807 22311 24665 23136 22065>,
			<13497 14071 22399 24685 24296 24356>,
			<13431 14330 22368 24635 24083 24328>,
			<13272 14599 22048 24291 21905 22029>,
			<13143 14823 21591 23799 20606 20662>,
			<13147 14968 20737 22559 21318 20816>,
			<13165 15050 20069 21284 21955 21161>,
			<13227 14748 19532 21208 22057 22122>,
			<13469 14281 19292 20924 20816 21662>,
			<13870 13655 19311 20332 20879 20381>,
			<14136 13768 16669 18865 19138 18994>,
			<14395 13799 16414 19234 18458 16855>,
			<14744 13945 14505 18003 18086 16013>,
			<15296 13689 14402 18596 16930 15505>,
			<16364 14527 14894 17984 16317 14958>,
			<15672 14705 14852 18626 17819 15853>,
			<15395 14475 14637 20437 19756 16606>,
			<15025 14418 14624 20505 21079 18319>,
			<13759 14491 14908 22459 25248 24604>,
			<13759 14491 14908 22459 25248 24604>,
			<13759 14491 14908 22459 25248 24604>;
	};

	qcom,pc-temp-y6-lut {
		qcom,lut-col-legend = <(-10) 0 10 25 40 50>;
		qcom,lut-row-legend = <10000 9800 9600 9400 9200 9000>,
			<8800 8600 8400 8200 8000 7800>,
			<7600 7400 7200 7000 6800 6600>,
			<6400 6200 6000 5800 5600 5400>,
			<5200 5000 4800 4600 4400 4200>,
			<4000 3800 3600 3400 3200 3000>,
			<2800 2600 2400 2200 2000 1800>,
			<1600 1400 1200 1000 900 800>,
			<700 600 500 400 300 200>,
			<100 0>;
		qcom,lut-data = <6298 5566 5244 5077 5042 5035>,
			<6250 5569 5243 5077 5042 5035>,
			<6203 5570 5242 5077 5042 5035>,
			<6160 5570 5241 5077 5043 5035>,
			<6122 5569 5241 5078 5043 5036>,
			<6093 5568 5240 5079 5044 5036>,
			<6073 5563 5240 5079 5044 5037>,
			<6055 5557 5239 5080 5045 5037>,
			<6029 5549 5240 5081 5046 5038>,
			<5997 5538 5241 5083 5047 5038>,
			<5986 5536 5243 5085 5048 5039>,
			<6013 5567 5248 5087 5049 5040>,
			<6041 5598 5255 5089 5051 5042>,
			<6003 5586 5261 5092 5053 5043>,
			<5899 5552 5266 5096 5055 5044>,
			<5859 5530 5267 5101 5058 5046>,
			<5857 5517 5263 5106 5061 5048>,
			<5855 5508 5259 5112 5064 5050>,
			<5852 5503 5257 5121 5070 5054>,
			<5848 5499 5255 5130 5076 5059>,
			<5844 5492 5248 5130 5080 5065>,
			<5838 5480 5228 5120 5083 5071>,
			<5834 5470 5211 5108 5084 5074>,
			<5834 5467 5203 5092 5067 5058>,
			<5835 5464 5198 5078 5045 5037>,
			<5837 5462 5196 5075 5042 5034>,
			<5845 5461 5196 5074 5041 5034>,
			<5855 5462 5195 5074 5041 5034>,
			<5867 5469 5194 5075 5042 5035>,
			<5882 5482 5193 5078 5044 5036>,
			<5899 5495 5194 5079 5046 5039>,
			<5919 5510 5196 5081 5050 5041>,
			<5941 5528 5199 5082 5052 5044>,
			<5965 5548 5205 5084 5054 5048>,
			<5992 5572 5212 5085 5055 5051>,
			<6020 5599 5221 5086 5054 5050>,
			<6051 5631 5231 5088 5052 5047>,
			<6085 5667 5242 5088 5050 5044>,
			<6123 5707 5255 5089 5048 5040>,
			<6163 5750 5269 5090 5047 5038>,
			<6205 5797 5285 5091 5050 5042>,
			<6250 5848 5303 5093 5053 5046>,
			<6305 5901 5325 5095 5054 5047>,
			<6372 5969 5349 5096 5050 5041>,
			<6379 5977 5339 5090 5042 5032>,
			<6471 6087 5388 5098 5049 5041>,
			<6534 6151 5423 5106 5056 5050>,
			<6601 6223 5464 5115 5067 5062>,
			<6669 6295 5517 5130 5080 5075>,
			<6749 6366 5575 5140 5085 5077>,
			<6831 6425 5616 5139 5070 5058>,
			<6940 6489 5679 5133 5061 5050>,
			<7175 6582 5812 5150 5068 5056>,
			<7937 6716 6006 5184 5089 5074>,
			<7937 6716 6006 5184 5089 5074>,
			<7937 6716 6006 5184 5089 5074>;
	};

};
